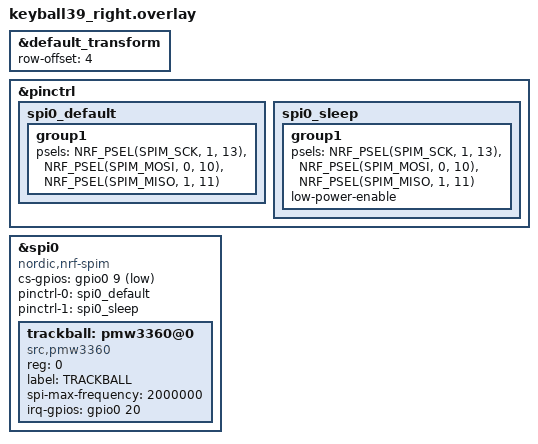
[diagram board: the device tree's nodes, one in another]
// zmk/app/boards/shields/keyball39/keyball39_right.overlay
#include "keyball39.dtsi"

&default_transform { // The matrix transform for this board is 4 rows over because the left half is 4 rows tall according to the matrix.
    row-offset = <4>;
};

&pinctrl {
    spi0_default: spi0_default {
        group1 {
            psels = <NRF_PSEL(SPIM_SCK, 1, 13)>,
                <NRF_PSEL(SPIM_MOSI, 0, 10)>,
                <NRF_PSEL(SPIM_MISO, 1, 11)>;
        };
    };

    spi0_sleep: spi0_sleep {
        group1 {
            psels = <NRF_PSEL(SPIM_SCK, 1, 13)>,
                <NRF_PSEL(SPIM_MOSI, 0, 10)>,
                <NRF_PSEL(SPIM_MISO, 1, 11)>;
            low-power-enable;
        };
    };
}; 

&spi0 {
	compatible = "nordic,nrf-spim";
	cs-gpios = <&gpio0 9 GPIO_ACTIVE_LOW>;
	status = "okay";
	pinctrl-0 = <&spi0_default>;
	pinctrl-1 = <&spi0_sleep>;
	pinctrl-names = "default", "sleep";
	trackball: pmw3360@0 {
		compatible = "src,pmw3360";
		status = "okay";
		reg = <0>;
		label = "TRACKBALL";
		spi-max-frequency = <2000000>;
		irq-gpios = <&gpio0 20 (GPIO_ACTIVE_HIGH | GPIO_PULL_DOWN)>;
		//duplex = <2048>; // required by 3-wire spi
	};
};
